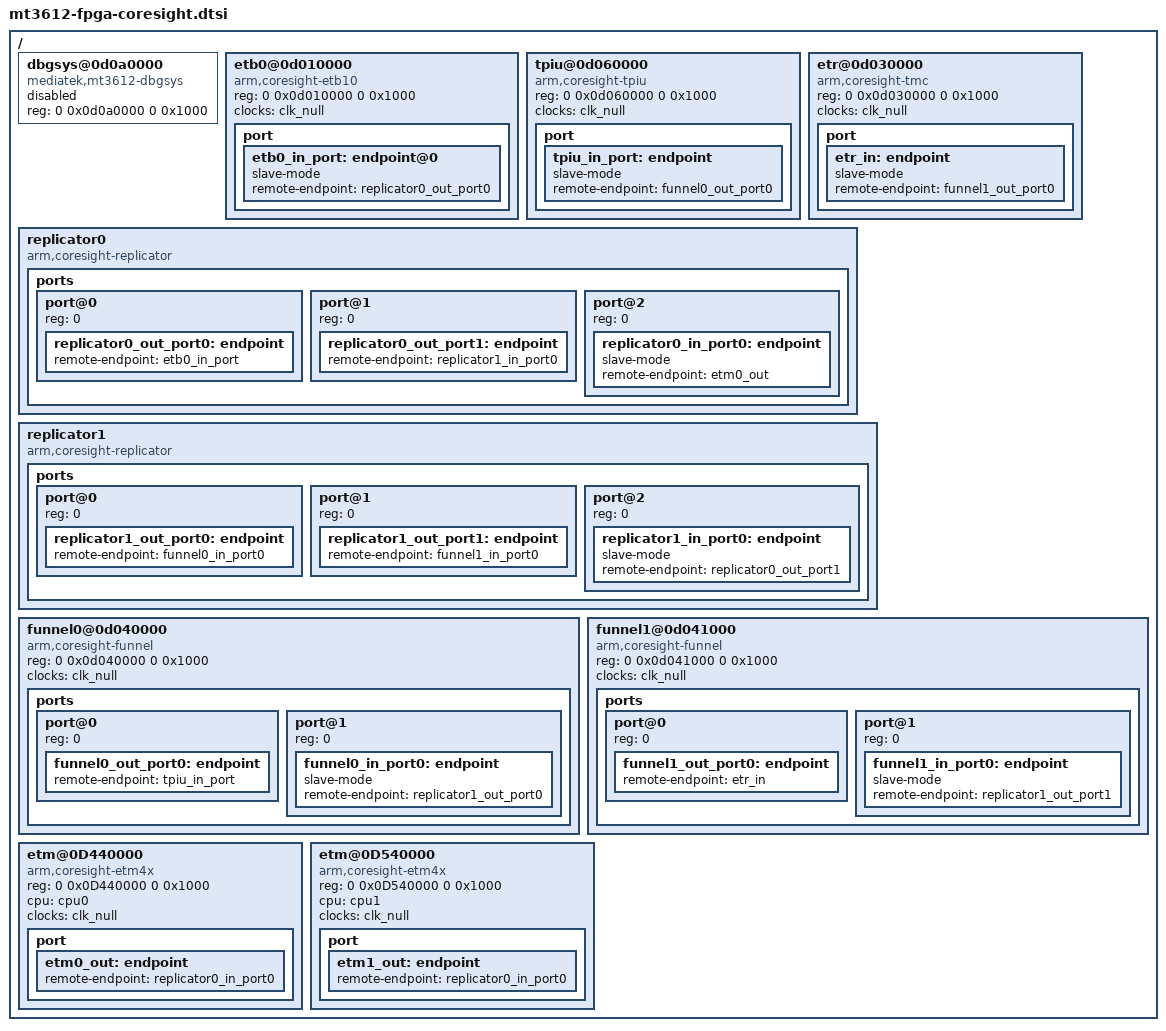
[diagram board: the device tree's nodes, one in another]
/*
 * Copyright (C) 2017 MediaTek Inc.
 *
 * This program is free software; you can redistribute it and/or modify
 * it under the terms of the GNU General Public License version 2 as
 * published by the Free Software Foundation.
 *
 * This program is distributed in the hope that it will be useful,
 * but WITHOUT ANY WARRANTY; without even the implied warranty of
 * MERCHANTABILITY or FITNESS FOR A PARTICULAR PURPOSE.
 * See http://www.gnu.org/licenses/gpl-2.0.html for more details.
 */

/ {
	dbgsys@0d0a0000 {
		compatible = "mediatek,mt3612-dbgsys";
		reg = <0 0x0d0a0000 0 0x1000>;
		status = "disabled";
	};

	etb0@0d010000 {
		compatible = "arm,coresight-etb10", "arm,primecell";
		reg = <0 0x0d010000 0 0x1000>;
		clocks = <&clk_null>;
		clock-names = "apb_pclk";
		port {
			etb0_in_port: endpoint@0 {
				slave-mode;
				remote-endpoint = <&replicator0_out_port0>;
			};
		};
	};

	tpiu@0d060000 {
		compatible = "arm,coresight-tpiu", "arm,primecell";
		reg = <0 0x0d060000 0 0x1000>;
		clocks = <&clk_null>;
		clock-names = "apb_pclk";
		port {
			tpiu_in_port: endpoint {
				slave-mode;
				remote-endpoint = <&funnel0_out_port0>;
			};
		};
	};

	etr@0d030000 {
		compatible = "arm,coresight-tmc", "arm,primecell";
		reg = <0 0x0d030000 0 0x1000>;
		clocks = <&clk_null>;
		clock-names = "apb_pclk";
		port {
			etr_in: endpoint {
				slave-mode;
				remote-endpoint = <&funnel1_out_port0>;
			};
		};
	};

	replicator0 {
		/* non-configurable replicators don't show up on the
		 * AMBA bus.  As such no need to add "arm,primecell".
		 */
		compatible = "arm,coresight-replicator";

		ports {
			#address-cells = <1>;
			#size-cells = <0>;

			/* replicator output ports */
			port@0 {
				reg = <0>;
				replicator0_out_port0: endpoint {
					remote-endpoint = <&etb0_in_port>;
				};
			};

			port@1 {
				reg = <0>;
				replicator0_out_port1: endpoint {
					remote-endpoint = <&replicator1_in_port0>;
				};
			};

			/* replicator input port */
			port@2 {
				reg = <0>;
				replicator0_in_port0: endpoint {
					slave-mode;
					remote-endpoint = <&etm0_out>;
				};
			};
		};
	};

	replicator1 {
		/* non-configurable replicators don't show up on the
		 * AMBA bus.  As such no need to add "arm,primecell".
		 */
		compatible = "arm,coresight-replicator";

		ports {
			#address-cells = <1>;
			#size-cells = <0>;

			/* replicator output ports */
			port@0 {
				reg = <0>;
				replicator1_out_port0: endpoint {
					remote-endpoint = <&funnel0_in_port0>;
				};
			};

			port@1 {
				reg = <0>;
				replicator1_out_port1: endpoint {
					remote-endpoint = <&funnel1_in_port0>;
				};
			};

			/* replicator input port */
			port@2 {
				reg = <0>;
				replicator1_in_port0: endpoint {
					slave-mode;
					remote-endpoint = <&replicator0_out_port1>;
				};
			};
		};
	};

	funnel0@0d040000 {
		compatible = "arm,coresight-funnel", "arm,primecell";
		reg = <0 0x0d040000 0 0x1000>;
		clocks = <&clk_null>;
		clock-names = "apb_pclk";
		ports {
			#address-cells = <1>;
			#size-cells = <0>;

			/* funnel output port */
			port@0 {
				reg = <0>;
				funnel0_out_port0: endpoint {
					remote-endpoint = <&tpiu_in_port>;
				};
			};

			/* funnel input port */
			port@1 {
				reg = <0>;
				funnel0_in_port0: endpoint {
					slave-mode;
					remote-endpoint = <&replicator1_out_port0>;
				};
			};
		};
	};

	funnel1@0d041000 {
		compatible = "arm,coresight-funnel", "arm,primecell";
		reg = <0 0x0d041000 0 0x1000>;
		clocks = <&clk_null>;
		clock-names = "apb_pclk";
		ports {
			#address-cells = <1>;
			#size-cells = <0>;

			/* funnel output port */
			port@0 {
				reg = <0>;
				funnel1_out_port0: endpoint {
					remote-endpoint = <&etr_in>;
				};
			};

			/* funnel input port */
			port@1 {
				reg = <0>;
				funnel1_in_port0: endpoint {
					slave-mode;
					remote-endpoint = <&replicator1_out_port1>;
				};
			};
		};
	};

	etm@0D440000 {
		compatible = "arm,coresight-etm4x", "arm,primecell";
		reg = <0 0x0D440000 0 0x1000>;
		cpu = <&cpu0>;
		clocks = <&clk_null>;
		clock-names = "apb_pclk";
		port {
			etm0_out: endpoint {
				remote-endpoint = <&replicator0_in_port0>;
			};
		};
	};

	etm@0D540000 {
		compatible = "arm,coresight-etm4x", "arm,primecell";
		reg = <0 0x0D540000 0 0x1000>;
		cpu = <&cpu1>;
		clocks = <&clk_null>;
		clock-names = "apb_pclk";
		port {
			etm1_out: endpoint {
				remote-endpoint = <&replicator0_in_port0>;
			};
		};
	};
};
